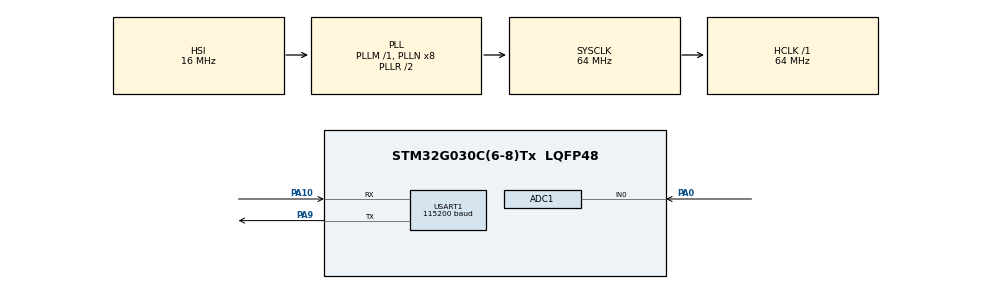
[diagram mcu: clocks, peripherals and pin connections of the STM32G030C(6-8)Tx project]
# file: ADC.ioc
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ADC1.Channel-0\#ChannelRegularConversion=ADC_CHANNEL_0
ADC1.Channel-IN0=ADC_CHANNEL_0
ADC1.ClockPrescaler=ADC_CLOCK_SYNC_PCLK_DIV2
ADC1.ContinuousConvMode=DISABLE
ADC1.DMAContinuousRequests=DISABLE
ADC1.DataAlign=ADC_DATAALIGN_RIGHT
ADC1.DiscontinuousConvMode=DISABLE
ADC1.EOCSelection=ADC_EOC_SINGLE_CONV
ADC1.EnableAnalogWatchDog1=false
ADC1.EnableAnalogWatchDog2=false
ADC1.EnableAnalogWatchDog3=false
ADC1.ExternalTrigConv=ADC_SOFTWARE_START
ADC1.ExternalTrigConvEdge=ADC_EXTERNALTRIGCONVEDGE_NONE
ADC1.LowPowerAutoPowerOff=DISABLE
ADC1.LowPowerAutoWait=DISABLE
ADC1.NbrOfConversion=1
ADC1.Overrun=ADC_OVR_DATA_PRESERVED
ADC1.OversamplingMode=DISABLE
ADC1.Rank-0\#ChannelRegularConversion=1
ADC1.Resolution=ADC_RESOLUTION_12B
ADC1.SamplingTime-0\#ChannelRegularConversion=ADC_SAMPLINGTIME_COMMON_1
ADC1.SamplingTimeCommon1=ADC_SAMPLETIME_1CYCLE_5
ADC1.SamplingTimeCommon2=ADC_SAMPLETIME_1CYCLE_5
ADC1.ScanConvMode=ADC_SCAN_DISABLE
ADC1.SelectedChannel=ADC_CHANNEL_0
ADC1.Sequencer=FULLY_CONFIGURABLE
ADC1.TriggerFrequencyMode=ADC_TRIGGER_FREQ_HIGH
ADC1.master=1
Mcu.Family=STM32G0
Mcu.Name=STM32G030C(6-8)Tx
Mcu.Package=LQFP48
PA0.Mode=IN0
PA0.Signal=ADC1_IN0
PA10.Mode=Asynchronous
PA10.Signal=USART1_RX
PA13.Mode=Serial_Wire
PA13.Signal=SYS_SWDIO
PA14-BOOT0.Mode=Serial_Wire
PA14-BOOT0.Signal=SYS_SWCLK
PA9.Mode=Asynchronous
PA9.Signal=USART1_TX
ProjectManager.HeapSize=0x200
ProjectManager.StackSize=0x400
ProjectManager.TargetToolchain=MDK-ARM V5.32
RCC.ADCFreq_Value=64000000
RCC.AHBFreq_Value=64000000
RCC.CortexFreq_Value=64000000
RCC.EXTERNAL_CLOCK_VALUE=12288000
RCC.FLatency=FLASH_LATENCY_2
RCC.HCLKFreq_Value=64000000
RCC.HSE_VALUE=8000000
RCC.HSI_VALUE=16000000
RCC.LSE_VALUE=32768
RCC.SYSCLKFreq_VALUE=64000000
RCC.SYSCLKSource=RCC_SYSCLKSOURCE_PLLCLK
RCC.VCOOutputFreq_Value=128000000
USART1.AutoBaudRateEnableParam=UART_ADVFEATURE_AUTOBAUDRATE_DISABLE
USART1.BaudRate=115200
USART1.ClockPrescaler=PRESCALER_DIV1
USART1.DMADisableonRxErrorParam=ADVFEATURE_DMA_ENABLEONRXERROR
USART1.DataInvertParam=ADVFEATURE_DATAINV_DISABLE
USART1.FIFOMode=FIFOMODE_DISABLE
USART1.MSBFirstParam=ADVFEATURE_MSBFIRST_DISABLE
USART1.Mode=MODE_TX_RX
USART1.OneBitSampling=UART_ONE_BIT_SAMPLE_DISABLE
USART1.OverSampling=UART_OVERSAMPLING_16
USART1.OverrunDisableParam=ADVFEATURE_OVERRUN_ENABLE
USART1.Parity=PARITY_NONE
USART1.RXFIFOThreshold=RXFIFO_THRESHOLD_1EIGHTHFULL
USART1.RxPinLevelInvertParam=ADVFEATURE_RXINV_DISABLE
USART1.StopBits=STOPBITS_1
USART1.SwapParam=ADVFEATURE_SWAP_DISABLE
USART1.TXFIFOThreshold=TXFIFO_THRESHOLD_1EIGHTHFULL
USART1.TxPinLevelInvertParam=ADVFEATURE_TXINV_DISABLE
USART1.VirtualMode-Asynchronous=VM_ASYNC
USART1.WordLength=WORDLENGTH_8B
board=custom

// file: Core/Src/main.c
/* USER CODE BEGIN Header */
/**
  ******************************************************************************
  * @file           : main.c
  * @brief          : Main program body
  ******************************************************************************
  * @attention
  *
  * <h2><center>&copy; Copyright (c) 2021 STMicroelectronics.
  * All rights reserved.</center></h2>
  *
  * This software component is licensed by ST under BSD 3-Clause license,
  * the "License"; You may not use this file except in compliance with the
  * License. You may obtain a copy of the License at:
  *                        opensource.org/licenses/BSD-3-Clause
  *
  ******************************************************************************
  */
/* USER CODE END Header */
#include "main.h"
#include "adc.h"
#include "usart.h"
#include "gpio.h"

/* USER CODE BEGIN Includes */
#include <stdio.h>
/* USER CODE END Includes */

void SystemClock_Config(void);

/* USER CODE BEGIN 0 */
int fputc(int ch, FILE *f)
{
    HAL_UART_Transmit(&huart1, (uint8_t *)&ch, 1, 1000);

    return ch;
}
/* USER CODE END 0 */

int main(void)
{
  /* USER CODE BEGIN 1 */
	uint16_t value = 0;
	float voltage = 0;
  /* USER CODE END 1 */

  /* MCU Configuration--------------------------------------------------------*/

  /* Reset of all peripherals, Initializes the Flash interface and the Systick. */
  HAL_Init();

  /* Configure the system clock */
  SystemClock_Config();

  /* Initialize all configured peripherals */
  MX_GPIO_Init();
  MX_ADC1_Init();
  MX_USART1_UART_Init();
  /* USER CODE BEGIN 2 */
	HAL_ADCEx_Calibration_Start(&hadc1);
  /* USER CODE END 2 */

  /* Infinite loop */
  /* USER CODE BEGIN WHILE */
  while (1)
  {
			HAL_Delay(1000);

			HAL_ADC_Start(&hadc1);
			HAL_ADC_PollForConversion(&hadc1, 100);
			value = HAL_ADC_GetValue(&hadc1);
			HAL_ADC_Stop(&hadc1);

			voltage = value*3.3/4096;
			printf("PA0 voltage %.2f\r\n", voltage);
    /* USER CODE END WHILE */

  }
}

void SystemClock_Config(void)
{
  RCC_OscInitTypeDef RCC_OscInitStruct = {0};
  RCC_ClkInitTypeDef RCC_ClkInitStruct = {0};
  RCC_PeriphCLKInitTypeDef PeriphClkInit = {0};

  /** Configure the main internal regulator output voltage
  */
  HAL_PWREx_ControlVoltageScaling(PWR_REGULATOR_VOLTAGE_SCALE1);
  /** Initializes the RCC Oscillators according to the specified parameters
  * in the RCC_OscInitTypeDef structure.
  */
  RCC_OscInitStruct.OscillatorType = RCC_OSCILLATORTYPE_HSI;
  RCC_OscInitStruct.HSIState = RCC_HSI_ON;
  RCC_OscInitStruct.HSIDiv = RCC_HSI_DIV1;
  RCC_OscInitStruct.HSICalibrationValue = RCC_HSICALIBRATION_DEFAULT;
  RCC_OscInitStruct.PLL.PLLState = RCC_PLL_ON;
  RCC_OscInitStruct.PLL.PLLSource = RCC_PLLSOURCE_HSI;
  RCC_OscInitStruct.PLL.PLLM = RCC_PLLM_DIV1;
  RCC_OscInitStruct.PLL.PLLN = 8;
  RCC_OscInitStruct.PLL.PLLP = RCC_PLLP_DIV2;
  RCC_OscInitStruct.PLL.PLLR = RCC_PLLR_DIV2;
  if (HAL_RCC_OscConfig(&RCC_OscInitStruct) != HAL_OK)
  {
    Error_Handler();
  }
  /** Initializes the CPU, AHB and APB buses clocks
  */
  RCC_ClkInitStruct.ClockType = RCC_CLOCKTYPE_HCLK|RCC_CLOCKTYPE_SYSCLK
                              |RCC_CLOCKTYPE_PCLK1;
  RCC_ClkInitStruct.SYSCLKSource = RCC_SYSCLKSOURCE_PLLCLK;
  RCC_ClkInitStruct.AHBCLKDivider = RCC_SYSCLK_DIV1;
  RCC_ClkInitStruct.APB1CLKDivider = RCC_HCLK_DIV1;

  if (HAL_RCC_ClockConfig(&RCC_ClkInitStruct, FLASH_LATENCY_2) != HAL_OK)
  {
    Error_Handler();
  }
  /** Initializes the peripherals clocks
  */
  PeriphClkInit.PeriphClockSelection = RCC_PERIPHCLK_USART1|RCC_PERIPHCLK_ADC;
  PeriphClkInit.Usart1ClockSelection = RCC_USART1CLKSOURCE_PCLK1;
  PeriphClkInit.AdcClockSelection = RCC_ADCCLKSOURCE_SYSCLK;
  if (HAL_RCCEx_PeriphCLKConfig(&PeriphClkInit) != HAL_OK)
  {
    Error_Handler();
  }
}

void Error_Handler(void)
{
  __disable_irq();
  while (1)
  {
  }
}

/************************ (C) COPYRIGHT STMicroelectronics *****END OF FILE****/
